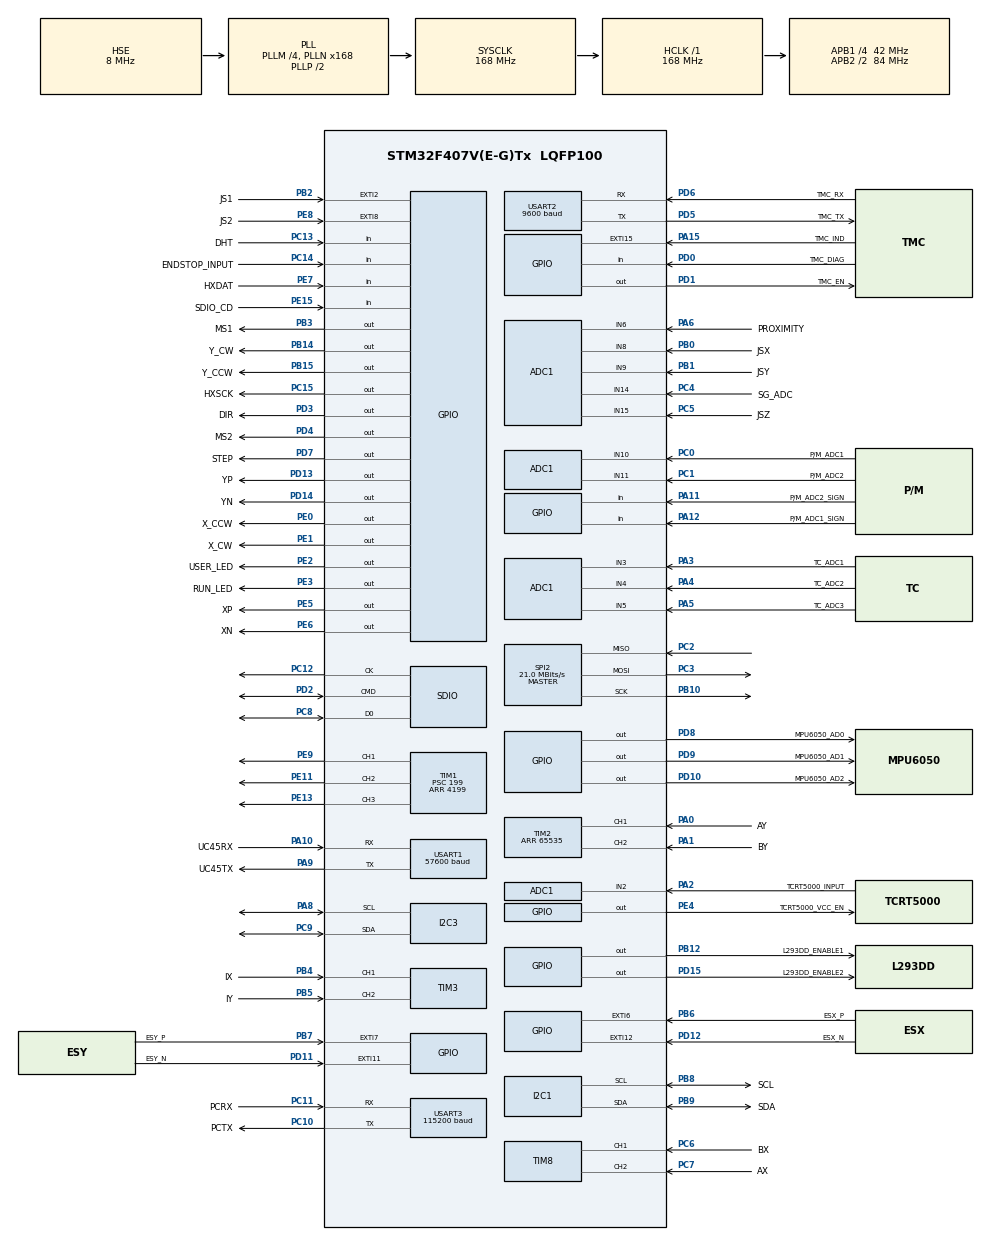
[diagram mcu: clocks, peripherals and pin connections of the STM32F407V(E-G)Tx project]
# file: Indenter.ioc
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ADC1.Channel-10\#ChannelRegularConversion=ADC_CHANNEL_6
ADC1.Channel-11\#ChannelRegularConversion=ADC_CHANNEL_8
ADC1.Channel-12\#ChannelRegularConversion=ADC_CHANNEL_9
ADC1.Channel-13\#ChannelRegularConversion=ADC_CHANNEL_10
ADC1.Channel-14\#ChannelRegularConversion=ADC_CHANNEL_11
ADC1.Channel-15\#ChannelRegularConversion=ADC_CHANNEL_14
ADC1.Channel-16\#ChannelRegularConversion=ADC_CHANNEL_15
ADC1.Channel-17\#ChannelRegularConversion=ADC_CHANNEL_TEMPSENSOR
ADC1.Channel-18\#ChannelRegularConversion=ADC_CHANNEL_VREFINT
ADC1.Channel-6\#ChannelRegularConversion=ADC_CHANNEL_2
ADC1.Channel-7\#ChannelRegularConversion=ADC_CHANNEL_3
ADC1.Channel-8\#ChannelRegularConversion=ADC_CHANNEL_4
ADC1.Channel-9\#ChannelRegularConversion=ADC_CHANNEL_5
ADC1.ContinuousConvMode=ENABLE
ADC1.DMAContinuousRequests=ENABLE
ADC1.EOCSelection=ADC_EOC_SEQ_CONV
ADC1.NbrOfConversion=13
ADC1.NbrOfConversionFlag=1
ADC1.Rank-10\#ChannelRegularConversion=5
ADC1.Rank-11\#ChannelRegularConversion=6
ADC1.Rank-12\#ChannelRegularConversion=7
ADC1.Rank-13\#ChannelRegularConversion=8
ADC1.Rank-14\#ChannelRegularConversion=9
ADC1.Rank-15\#ChannelRegularConversion=10
ADC1.Rank-16\#ChannelRegularConversion=11
ADC1.Rank-17\#ChannelRegularConversion=12
ADC1.Rank-18\#ChannelRegularConversion=13
ADC1.Rank-6\#ChannelRegularConversion=1
ADC1.Rank-7\#ChannelRegularConversion=2
ADC1.Rank-8\#ChannelRegularConversion=3
ADC1.Rank-9\#ChannelRegularConversion=4
ADC1.SamplingTime-10\#ChannelRegularConversion=ADC_SAMPLETIME_28CYCLES
ADC1.SamplingTime-11\#ChannelRegularConversion=ADC_SAMPLETIME_28CYCLES
ADC1.SamplingTime-12\#ChannelRegularConversion=ADC_SAMPLETIME_28CYCLES
ADC1.SamplingTime-13\#ChannelRegularConversion=ADC_SAMPLETIME_28CYCLES
ADC1.SamplingTime-14\#ChannelRegularConversion=ADC_SAMPLETIME_28CYCLES
ADC1.SamplingTime-15\#ChannelRegularConversion=ADC_SAMPLETIME_28CYCLES
ADC1.SamplingTime-16\#ChannelRegularConversion=ADC_SAMPLETIME_28CYCLES
ADC1.SamplingTime-17\#ChannelRegularConversion=ADC_SAMPLETIME_28CYCLES
ADC1.SamplingTime-18\#ChannelRegularConversion=ADC_SAMPLETIME_28CYCLES
ADC1.SamplingTime-6\#ChannelRegularConversion=ADC_SAMPLETIME_28CYCLES
ADC1.SamplingTime-7\#ChannelRegularConversion=ADC_SAMPLETIME_28CYCLES
ADC1.SamplingTime-8\#ChannelRegularConversion=ADC_SAMPLETIME_28CYCLES
ADC1.SamplingTime-9\#ChannelRegularConversion=ADC_SAMPLETIME_28CYCLES
ADC1.master=1
Dma.ADC1.0.Direction=DMA_PERIPH_TO_MEMORY
Dma.ADC1.0.FIFOMode=DMA_FIFOMODE_DISABLE
Dma.ADC1.0.Instance=DMA2_Stream0
Dma.ADC1.0.MemDataAlignment=DMA_MDATAALIGN_HALFWORD
Dma.ADC1.0.MemInc=DMA_MINC_ENABLE
Dma.ADC1.0.Mode=DMA_CIRCULAR
Dma.ADC1.0.PeriphDataAlignment=DMA_PDATAALIGN_HALFWORD
Dma.ADC1.0.PeriphInc=DMA_PINC_DISABLE
Dma.ADC1.0.Priority=DMA_PRIORITY_LOW
Dma.Request0=ADC1
FATFS.BSP.number=1
FATFS0.BSP.STBoard=false
FATFS0.BSP.api=Unknown
FATFS0.BSP.i2caddr=0
FATFS0.BSP.instance=PE15
FATFS0.BSP.ip=GPIO
FATFS0.BSP.mode=Input
FATFS0.BSP.name=Detect_SDIO
FATFS0.BSP.solution=PE15
Mcu.Family=STM32F4
Mcu.Name=STM32F407V(E-G)Tx
Mcu.Package=LQFP100
NVIC.DMA2_Stream0_IRQn=true\:2\:0\:true\:false\:true\:false\:true
NVIC.EXTI15_10_IRQn=true\:2\:0\:true\:false\:true\:true\:true
NVIC.EXTI2_IRQn=true\:2\:0\:true\:false\:true\:true\:true
NVIC.EXTI9_5_IRQn=true\:2\:0\:true\:false\:true\:true\:true
NVIC.PriorityGroup=NVIC_PRIORITYGROUP_4
NVIC.TIM1_BRK_TIM9_IRQn=true\:2\:0\:true\:false\:true\:true\:true
NVIC.TIM1_TRG_COM_TIM11_IRQn=true\:2\:0\:true\:false\:true\:true\:true
NVIC.TIM1_UP_TIM10_IRQn=true\:2\:0\:true\:false\:true\:true\:true
NVIC.TIM8_BRK_TIM12_IRQn=true\:2\:0\:true\:false\:true\:true\:true
NVIC.TIM8_UP_TIM13_IRQn=true\:2\:0\:true\:false\:true\:true\:true
NVIC.USART1_IRQn=true\:1\:0\:true\:false\:true\:true\:true
NVIC.USART2_IRQn=true\:1\:0\:true\:false\:true\:true\:true
NVIC.USART3_IRQn=true\:1\:0\:true\:false\:true\:true\:true
PA0-WKUP.GPIO_Label=AY
PA0-WKUP.Signal=S_TIM2_CH1_ETR
PA1.GPIO_Label=BY
PA1.Signal=S_TIM2_CH2
PA10.GPIO_Label=UC45RX
PA10.Mode=Asynchronous
PA10.Signal=USART1_RX
PA11.GPIO_Label=P/M_ADC2_SIGN
PA11.Signal=GPIO_Input
PA12.GPIO_Label=P/M_ADC1_SIGN
PA12.Signal=GPIO_Input
PA13.Mode=Serial_Wire
PA13.Signal=SYS_JTMS-SWDIO
PA14.Mode=Serial_Wire
PA14.Signal=SYS_JTCK-SWCLK
PA15.GPIO_Label=TMC_IND
PA15.Signal=GPXTI15
PA2.GPIO_Label=TCRT5000_INPUT
PA2.Signal=ADCx_IN2
PA3.GPIO_Label=TC_ADC1
PA3.Signal=ADCx_IN3
PA4.GPIO_Label=TC_ADC2
PA4.Signal=ADCx_IN4
PA5.GPIO_Label=TC_ADC3
PA5.Signal=ADCx_IN5
PA6.GPIO_Label=PROXIMITY
PA6.Signal=ADCx_IN6
PA8.Mode=I2C
PA8.Signal=I2C3_SCL
PA9.GPIO_Label=UC45TX
PA9.Mode=Asynchronous
PA9.Signal=USART1_TX
PB0.GPIO_Label=JSX
PB0.Signal=ADCx_IN8
PB1.GPIO_Label=JSY
PB1.Signal=ADCx_IN9
PB10.Mode=Full_Duplex_Master
PB10.Signal=SPI2_SCK
PB12.GPIO_Label=L293DD_ENABLE1
PB12.Signal=GPIO_Output
PB14.GPIO_Label=Y_CW
PB14.Signal=GPIO_Output
PB15.GPIO_Label=Y_CCW
PB15.Signal=GPIO_Output
PB2.GPIO_Label=JS1
PB2.GPIO_ModeDefaultEXTI=GPIO_MODE_IT_FALLING
PB2.GPIO_PuPd=GPIO_PULLUP
PB2.Signal=GPXTI2
PB3.GPIO_Label=MS1
PB3.Signal=GPIO_Output
PB4.GPIO_Label=IX
PB4.Signal=S_TIM3_CH1
PB5.GPIO_Label=IY
PB5.Signal=S_TIM3_CH2
PB6.GPIO_Label=ESX_P
PB6.GPIO_ModeDefaultEXTI=GPIO_MODE_IT_RISING_FALLING
PB6.Signal=GPXTI6
PB7.GPIO_Label=ESY_P
PB7.GPIO_ModeDefaultEXTI=GPIO_MODE_IT_RISING_FALLING
PB7.Signal=GPXTI7
PB8.GPIO_Label=SCL
PB8.Mode=I2C
PB8.Signal=I2C1_SCL
PB9.GPIO_Label=SDA
PB9.Mode=I2C
PB9.Signal=I2C1_SDA
PC0.GPIO_Label=P/M_ADC1
PC0.Signal=ADCx_IN10
PC1.GPIO_Label=P/M_ADC2
PC1.Signal=ADCx_IN11
PC10.GPIO_Label=PCTX
PC10.Mode=Asynchronous
PC10.Signal=USART3_TX
PC11.GPIO_Label=PCRX
PC11.Mode=Asynchronous
PC11.Signal=USART3_RX
PC12.Mode=SD_1_bit
PC12.Signal=SDIO_CK
PC13-ANTI_TAMP.GPIO_Label=DHT
PC13-ANTI_TAMP.Signal=GPIO_Input
PC14-OSC32_IN.GPIO_Label=ENDSTOP_INPUT
PC14-OSC32_IN.Signal=GPIO_Input
PC15-OSC32_OUT.GPIO_Label=HXSCK
PC15-OSC32_OUT.Signal=GPIO_Output
PC2.Mode=Full_Duplex_Master
PC2.Signal=SPI2_MISO
PC3.Mode=Full_Duplex_Master
PC3.Signal=SPI2_MOSI
PC4.GPIO_Label=SG_ADC
PC4.Signal=ADCx_IN14
PC5.GPIO_Label=JSZ
PC5.Signal=ADCx_IN15
PC6.GPIO_Label=BX
PC6.Signal=S_TIM8_CH1
PC7.GPIO_Label=AX
PC7.Signal=S_TIM8_CH2
PC8.Mode=SD_1_bit
PC8.Signal=SDIO_D0
PC9.Mode=I2C
PC9.Signal=I2C3_SDA
PD0.GPIO_Label=TMC_DIAG
PD0.Signal=GPIO_Input
PD1.GPIO_Label=TMC_EN
PD1.Signal=GPIO_Output
PD10.GPIO_Label=MPU6050_AD2
PD10.Signal=GPIO_Output
PD11.GPIO_Label=ESY_N
PD11.GPIO_ModeDefaultEXTI=GPIO_MODE_IT_RISING_FALLING
PD11.Signal=GPXTI11
PD12.GPIO_Label=ESX_N
PD12.GPIO_ModeDefaultEXTI=GPIO_MODE_IT_RISING_FALLING
PD12.Signal=GPXTI12
PD13.GPIO_Label=YP
PD13.Signal=GPIO_Output
PD14.GPIO_Label=YN
PD14.Signal=GPIO_Output
PD15.GPIO_Label=L293DD_ENABLE2
PD15.Signal=GPIO_Output
PD2.Mode=SD_1_bit
PD2.Signal=SDIO_CMD
PD3.GPIO_Label=DIR
PD3.Signal=GPIO_Output
PD4.GPIO_Label=MS2
PD4.Signal=GPIO_Output
PD5.GPIO_Label=TMC_TX
PD5.Mode=Asynchronous
PD5.Signal=USART2_TX
PD6.GPIO_Label=TMC_RX
PD6.Mode=Asynchronous
PD6.Signal=USART2_RX
PD7.GPIO_Label=STEP
PD7.Signal=GPIO_Output
PD8.GPIO_Label=MPU6050_AD0
PD8.Signal=GPIO_Output
PD9.GPIO_Label=MPU6050_AD1
PD9.Signal=GPIO_Output
PE0.GPIO_Label=X_CCW
PE0.Signal=GPIO_Output
PE1.GPIO_Label=X_CW
PE1.Signal=GPIO_Output
PE11.GPIO_ModeDefaultPP=GPIO_MODE_AF_PP
PE11.GPIO_PuPd=GPIO_NOPULL
PE11.GPIO_Speed=GPIO_SPEED_FREQ_LOW
PE11.Signal=S_TIM1_CH2
PE13.GPIO_ModeDefaultPP=GPIO_MODE_AF_PP
PE13.GPIO_PuPd=GPIO_NOPULL
PE13.GPIO_Speed=GPIO_SPEED_FREQ_LOW
PE13.Signal=S_TIM1_CH3
PE15.GPIO_Label=SDIO_CD
PE15.Signal=GPIO_Input
PE2.GPIO_Label=USER_LED
PE2.Signal=GPIO_Output
PE3.GPIO_Label=RUN_LED
PE3.Signal=GPIO_Output
PE4.GPIO_Label=TCRT5000_VCC_EN
PE4.Signal=GPIO_Output
PE5.GPIO_Label=XP
PE5.Signal=GPIO_Output
PE6.GPIO_Label=XN
PE6.Signal=GPIO_Output
PE7.GPIO_Label=HXDAT
PE7.Signal=GPIO_Input
PE8.GPIO_Label=JS2
PE8.GPIO_ModeDefaultEXTI=GPIO_MODE_IT_FALLING
PE8.GPIO_PuPd=GPIO_PULLUP
PE8.Signal=GPXTI8
PE9.GPIO_ModeDefaultPP=GPIO_MODE_AF_PP
PE9.GPIO_PuPd=GPIO_NOPULL
PE9.GPIO_Speed=GPIO_SPEED_FREQ_LOW
PE9.Signal=S_TIM1_CH1
PH0-OSC_IN.Mode=HSE-External-Oscillator
PH0-OSC_IN.Signal=RCC_OSC_IN
PH1-OSC_OUT.Mode=HSE-External-Oscillator
PH1-OSC_OUT.Signal=RCC_OSC_OUT
ProjectManager.HeapSize=0x200
ProjectManager.StackSize=0x400
ProjectManager.TargetToolchain=STM32CubeIDE
RCC.48MHZClocksFreq_Value=48000000
RCC.AHBFreq_Value=168000000
RCC.APB1CLKDivider=RCC_HCLK_DIV4
RCC.APB1Freq_Value=42000000
RCC.APB1TimFreq_Value=84000000
RCC.APB2CLKDivider=RCC_HCLK_DIV2
RCC.APB2Freq_Value=84000000
RCC.APB2TimFreq_Value=168000000
RCC.CortexFreq_Value=168000000
RCC.HCLKFreq_Value=168000000
RCC.HSE_VALUE=8000000
RCC.HSI_VALUE=16000000
RCC.LSE_VALUE=32768
RCC.PLLM=4
RCC.PLLN=168
RCC.PLLQ=7
RCC.PLLSourceVirtual=RCC_PLLSOURCE_HSE
RCC.SYSCLKFreq_VALUE=168000000
RCC.SYSCLKSource=RCC_SYSCLKSOURCE_PLLCLK
RCC.VCOOutputFreq_Value=336000000
SH.ADCx_IN10.0=ADC1_IN10,IN10
SH.ADCx_IN11.0=ADC1_IN11,IN11
SH.ADCx_IN14.0=ADC1_IN14,IN14
SH.ADCx_IN15.0=ADC1_IN15,IN15
SH.ADCx_IN2.0=ADC1_IN2,IN2
SH.ADCx_IN3.0=ADC1_IN3,IN3
SH.ADCx_IN4.0=ADC1_IN4,IN4
SH.ADCx_IN5.0=ADC1_IN5,IN5
SH.ADCx_IN6.0=ADC1_IN6,IN6
SH.ADCx_IN8.0=ADC1_IN8,IN8
SH.ADCx_IN9.0=ADC1_IN9,IN9
SH.S_TIM1_CH1.0=TIM1_CH1,PWM Generation1 CH1
SH.S_TIM1_CH2.0=TIM1_CH2,PWM Generation2 CH2
SH.S_TIM1_CH3.0=TIM1_CH3,PWM Generation3 CH3
SH.S_TIM2_CH1_ETR.0=TIM2_CH1,Encoder_Interface
SH.S_TIM2_CH2.0=TIM2_CH2,Encoder_Interface
SH.S_TIM3_CH1.0=TIM3_CH1,Encoder_Interface
SH.S_TIM3_CH2.0=TIM3_CH2,Encoder_Interface
SH.S_TIM8_CH1.0=TIM8_CH1,Encoder_Interface
SH.S_TIM8_CH2.0=TIM8_CH2,Encoder_Interface
SPI2.BaudRatePrescaler=SPI_BAUDRATEPRESCALER_2
SPI2.CalculateBaudRate=21.0 MBits/s
SPI2.Direction=SPI_DIRECTION_2LINES
SPI2.Mode=SPI_MODE_MASTER
SPI2.VirtualType=VM_MASTER
TIM1.Channel-PWM\ Generation1\ CH1=TIM_CHANNEL_1
TIM1.Channel-PWM\ Generation2\ CH2=TIM_CHANNEL_2
TIM1.Channel-PWM\ Generation3\ CH3=TIM_CHANNEL_3
TIM1.Period=4199
TIM1.Prescaler=199
TIM2.AutoReloadPreload=TIM_AUTORELOAD_PRELOAD_ENABLE
TIM2.EncoderMode=TIM_ENCODERMODE_TI12
TIM2.IC1Filter=0
TIM2.IC2Filter=0
TIM2.Period=65535
TIM3.AutoReloadPreload=TIM_AUTORELOAD_PRELOAD_ENABLE
TIM3.EncoderMode=TIM_ENCODERMODE_TI12
TIM3.IC1Filter=0
TIM3.IC2Filter=0
TIM8.AutoReloadPreload=TIM_AUTORELOAD_PRELOAD_ENABLE
TIM8.EncoderMode=TIM_ENCODERMODE_TI12
TIM8.IC1Filter=0
TIM8.IC2Filter=0
USART1.BaudRate=57600
USART1.VirtualMode=VM_ASYNC
USART2.BaudRate=9600
USART2.VirtualMode=VM_ASYNC
USART3.BaudRate=115200
USART3.VirtualMode=VM_ASYNC
VP_ADC1_TempSens_Input.Mode=IN-TempSens
VP_ADC1_Vref_Input.Mode=IN-Vrefint
VP_FATFS_VS_SDIO.Mode=SDIO
VP_TIM10_VS_ClockSourceINT.Mode=Enable_Timer
VP_TIM11_VS_ClockSourceINT.Mode=Enable_Timer
VP_TIM12_VS_ClockSourceINT.Mode=Internal
VP_TIM13_VS_ClockSourceINT.Mode=Enable_Timer
VP_TIM9_VS_ClockSourceINT.Mode=Internal
board=custom

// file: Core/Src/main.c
/* USER CODE BEGIN Header */
/**
 * INDENTER CONTROL CARD V1 PROGRAM
  ******************************************************************************
  * @file           : main.c
  * @brief          : Main program body
  ******************************************************************************
  * @attention
  *
  * <h2><center>&copy; Copyright (c) 2021 STMicroelectronics.
  * All rights reserved.</center></h2>
  *
  * This software component is licensed by ST under BSD 3-Clause license,
  * the "License"; You may not use this file except in compliance with the
  * License. You may obtain a copy of the License at:
  *                        opensource.org/licenses/BSD-3-Clause
  *
  ******************************************************************************
  */
/* USER CODE END Header */
#include "main.h"
#include "fatfs.h"

/* USER CODE BEGIN Includes */
#include "stdio.h"
#include "struct.h"
#include "string.h"
#include "stdint.h"
#include "stdlib.h"
#include "math.h"
#include "timer.h"
#include "uart.h"
#include "adc.h"
#include "HX711.h"
#include "DHT.h"
#include "accel.h"
#include "experiment.h"
#include "ext_it.h"
#include "heater.h"
#include "encoder.h"
#include "pc_uart.h"
/* USER CODE END Includes */

/* USER CODE BEGIN PD */
#define DEBUG 1

#define UC45_RESP				1

#define DATA_FLASH_START_ADDR 0x800F000

/* USER CODE END PD */

/* USER CODE BEGIN PM */
#if DEBUG == 1
#define consoleWrite(args ...) printf(args)
#else
#define consoleWrite(args ...)
#endif

/* USER CODE END PM */

ADC_HandleTypeDef hadc1;
DMA_HandleTypeDef hdma_adc1;

I2C_HandleTypeDef hi2c1;
I2C_HandleTypeDef hi2c3;

SD_HandleTypeDef hsd;

SPI_HandleTypeDef hspi2;

TIM_HandleTypeDef htim1;
TIM_HandleTypeDef htim2;
TIM_HandleTypeDef htim3;
TIM_HandleTypeDef htim8;
TIM_HandleTypeDef htim9;
TIM_HandleTypeDef htim10;
TIM_HandleTypeDef htim11;
TIM_HandleTypeDef htim12;
TIM_HandleTypeDef htim13;

UART_HandleTypeDef huart1;
UART_HandleTypeDef huart2;
UART_HandleTypeDef huart3;

/* USER CODE BEGIN PV */

INITIALCOM INIT0;
EXPERIMENT expin[100];
EXPERIMENTrx exprx[100];
CALIBRATION calib;
CALIBRATIONrx calibrx;

//DHT
DHT_DataTypedef instanthum;

//HX711
HX711 instant;
int tmpVal;
//Accelerometer
uint16_t mpu[3] = {0};
//adc
char datasender[30];
uint32_t adcBuff[1300] = {0};
uint16_t adcData[13] = {0};
int extcon=0;
int joyen=0;
int joyint1=0;
int joyint2=0;
int delaymic=0;
int loadcon=0;
int contact=0;
int contsend=0;

extern int speedmode;
extern int pccom;
extern UARTCOM * _uartcom3;
extern UARTCOM pcInit;
extern int sendexp;//timer2 control execute exp
extern int stopmot;
extern int osc;//timer2 control oscillation activate
extern int retracting;
extern int automot;
extern int dir;
extern int sensdist;
extern int eqstep;
extern enum approach app;
extern uint8_t isAutoApproach;
extern int stepsay;
uint8_t dcMotor = 1;
uint16_t adcVal[13];
uint8_t kilo;
extern uint32_t x_enc[2];
extern uint32_t y_enc[2];
extern uint32_t i_enc[2];
extern int movxy;
extern int heatDuty[3];

int isHXcom=0;

/* USER CODE END PV */

void SystemClock_Config(void);
static void MX_GPIO_Init(void);
static void MX_DMA_Init(void);
static void MX_TIM8_Init(void);
static void MX_I2C3_Init(void);
static void MX_USART1_UART_Init(void);
static void MX_I2C1_Init(void);
static void MX_SPI2_Init(void);
static void MX_SDIO_SD_Init(void);
static void MX_USART2_UART_Init(void);
static void MX_USART3_UART_Init(void);
static void MX_TIM2_Init(void);
static void MX_TIM3_Init(void);
static void MX_ADC1_Init(void);
static void MX_TIM1_Init(void);
static void MX_TIM9_Init(void);
static void MX_TIM10_Init(void);
static void MX_TIM11_Init(void);
static void MX_TIM12_Init(void);
static void MX_TIM13_Init(void);

/* USER CODE BEGIN 0 */
int _write(int file, char *ptr, int len)
{
	int DataIdx;

	for (DataIdx = 0; DataIdx < len; DataIdx++)
	{
		ITM_SendChar(*ptr++);
	}
	return len;
}

/* USER CODE END 0 */

int main(void)
{
  /* USER CODE BEGIN 1 */
	char strArr[10];
  /* USER CODE END 1 */

  /* MCU Configuration--------------------------------------------------------*/

  /* Reset of all peripherals, Initializes the Flash interface and the Systick. */
  HAL_Init();

  /* USER CODE BEGIN Init */
  UartInit();
  /* USER CODE END Init */

  /* Initialize all configured peripherals */
  MX_GPIO_Init();
  MX_DMA_Init();
  MX_TIM8_Init();
  MX_I2C3_Init();
  MX_USART1_UART_Init();
  MX_I2C1_Init();
  MX_SPI2_Init();
  MX_SDIO_SD_Init();
  MX_USART2_UART_Init();
  MX_USART3_UART_Init();
  MX_TIM2_Init();
  MX_TIM3_Init();
  MX_ADC1_Init();
  MX_TIM1_Init();
  MX_TIM9_Init();
  MX_TIM10_Init();
  MX_TIM11_Init();
  MX_TIM12_Init();
  MX_FATFS_Init();
  MX_TIM13_Init();
  /* USER CODE BEGIN 2 */
  instant.gpioData = HXDAT_GPIO_Port;
  instant.gpioSck = HXSCK_GPIO_Port;
  instant.pinData = HXDAT_Pin;
  instant.pinSck = HXSCK_Pin;
  instant.gain = 3;
  HX711_Init(instant);
  instant = HX711_Tare(instant, 15);
  uint32_t flashsize =*(uint32_t *) FLASHSIZE_BASE;
  UNUSED(flashsize);
  HAL_ADC_Start_DMA(&hadc1, adcBuff, 1300);
  HAL_GPIO_WritePin(TMC_EN_GPIO_Port, TMC_EN_Pin,GPIO_PIN_SET);
  TimeSet(&htim11, 100000);
  HAL_TIM_Encoder_Start(&htim2, TIM_CHANNEL_ALL);
  HAL_TIM_Encoder_Start(&htim8, TIM_CHANNEL_ALL);
  __HAL_TIM_SET_COMPARE(&htim1,TIM_CHANNEL_1,0);
  __HAL_TIM_SET_COMPARE(&htim1,TIM_CHANNEL_2,0);
  __HAL_TIM_SET_COMPARE(&htim1,TIM_CHANNEL_3,0);
  HAL_TIM_PWM_Start(&htim1, TIM_CHANNEL_1);
  HAL_TIM_PWM_Start(&htim1, TIM_CHANNEL_2);
  HAL_TIM_PWM_Start(&htim1, TIM_CHANNEL_3);
  TimeSet(&htim13, 100000);
  TimeSet(&htim12, 10000);
  /* USER CODE END 2 */

  /* Infinite loop */
  /* USER CODE BEGIN WHILE */
  while (1)
  {
	  if(isAutoApproach==1){
		  isAutoApproach=6;
		  autoApproach(-1);
	  }
    /* USER CODE END WHILE */

  }
}

void SystemClock_Config(void)
{
  RCC_OscInitTypeDef RCC_OscInitStruct = {0};
  RCC_ClkInitTypeDef RCC_ClkInitStruct = {0};

  /** Configure the main internal regulator output voltage
  */
  __HAL_RCC_PWR_CLK_ENABLE();
  __HAL_PWR_VOLTAGESCALING_CONFIG(PWR_REGULATOR_VOLTAGE_SCALE1);
  /** Initializes the RCC Oscillators according to the specified parameters
  * in the RCC_OscInitTypeDef structure.
  */
  RCC_OscInitStruct.OscillatorType = RCC_OSCILLATORTYPE_HSE;
  RCC_OscInitStruct.HSEState = RCC_HSE_ON;
  RCC_OscInitStruct.PLL.PLLState = RCC_PLL_ON;
  RCC_OscInitStruct.PLL.PLLSource = RCC_PLLSOURCE_HSE;
  RCC_OscInitStruct.PLL.PLLM = 4;
  RCC_OscInitStruct.PLL.PLLN = 168;
  RCC_OscInitStruct.PLL.PLLP = RCC_PLLP_DIV2;
  RCC_OscInitStruct.PLL.PLLQ = 7;
  if (HAL_RCC_OscConfig(&RCC_OscInitStruct) != HAL_OK)
  {
    Error_Handler();
  }
  /** Initializes the CPU, AHB and APB buses clocks
  */
  RCC_ClkInitStruct.ClockType = RCC_CLOCKTYPE_HCLK|RCC_CLOCKTYPE_SYSCLK
                              |RCC_CLOCKTYPE_PCLK1|RCC_CLOCKTYPE_PCLK2;
  RCC_ClkInitStruct.SYSCLKSource = RCC_SYSCLKSOURCE_PLLCLK;
  RCC_ClkInitStruct.AHBCLKDivider = RCC_SYSCLK_DIV1;
  RCC_ClkInitStruct.APB1CLKDivider = RCC_HCLK_DIV4;
  RCC_ClkInitStruct.APB2CLKDivider = RCC_HCLK_DIV2;

  if (HAL_RCC_ClockConfig(&RCC_ClkInitStruct, FLASH_LATENCY_5) != HAL_OK)
  {
    Error_Handler();
  }
}

static void MX_ADC1_Init(void)
{

  ADC_ChannelConfTypeDef sConfig = {0};

  /** Configure the global features of the ADC (Clock, Resolution, Data Alignment and number of conversion)
  */
  hadc1.Instance = ADC1;
  hadc1.Init.ClockPrescaler = ADC_CLOCK_SYNC_PCLK_DIV4;
  hadc1.Init.Resolution = ADC_RESOLUTION_12B;
  hadc1.Init.ScanConvMode = ENABLE;
  hadc1.Init.ContinuousConvMode = ENABLE;
  hadc1.Init.DiscontinuousConvMode = DISABLE;
  hadc1.Init.ExternalTrigConvEdge = ADC_EXTERNALTRIGCONVEDGE_NONE;
  hadc1.Init.ExternalTrigConv = ADC_SOFTWARE_START;
  hadc1.Init.DataAlign = ADC_DATAALIGN_RIGHT;
  hadc1.Init.NbrOfConversion = 13;
  hadc1.Init.DMAContinuousRequests = ENABLE;
  hadc1.Init.EOCSelection = ADC_EOC_SEQ_CONV;
  if (HAL_ADC_Init(&hadc1) != HAL_OK)
  {
    Error_Handler();
  }
  /** Configure for the selected ADC regular channel its corresponding rank in the sequencer and its sample time.
  */
  sConfig.Channel = ADC_CHANNEL_2;
  sConfig.Rank = 1;
  sConfig.SamplingTime = ADC_SAMPLETIME_28CYCLES;
  if (HAL_ADC_ConfigChannel(&hadc1, &sConfig) != HAL_OK)
  {
    Error_Handler();
  }
  /** Configure for the selected ADC regular channel its corresponding rank in the sequencer and its sample time.
  */
  sConfig.Channel = ADC_CHANNEL_3;
  sConfig.Rank = 2;
  if (HAL_ADC_ConfigChannel(&hadc1, &sConfig) != HAL_OK)
  {
    Error_Handler();
  }
  /** Configure for the selected ADC regular channel its corresponding rank in the sequencer and its sample time.
  */
  sConfig.Channel = ADC_CHANNEL_4;
  sConfig.Rank = 3;
  if (HAL_ADC_ConfigChannel(&hadc1, &sConfig) != HAL_OK)
  {
    Error_Handler();
  }
  /** Configure for the selected ADC regular channel its corresponding rank in the sequencer and its sample time.
  */
  sConfig.Channel = ADC_CHANNEL_5;
  sConfig.Rank = 4;
  if (HAL_ADC_ConfigChannel(&hadc1, &sConfig) != HAL_OK)
  {
    Error_Handler();
  }
  /** Configure for the selected ADC regular channel its corresponding rank in the sequencer and its sample time.
  */
  sConfig.Channel = ADC_CHANNEL_6;
  sConfig.Rank = 5;
  if (HAL_ADC_ConfigChannel(&hadc1, &sConfig) != HAL_OK)
  {
    Error_Handler();
  }
  /** Configure for the selected ADC regular channel its corresponding rank in the sequencer and its sample time.
  */
  sConfig.Channel = ADC_CHANNEL_8;
  sConfig.Rank = 6;
  if (HAL_ADC_ConfigChannel(&hadc1, &sConfig) != HAL_OK)
  {
    Error_Handler();
  }
  /** Configure for the selected ADC regular channel its corresponding rank in the sequencer and its sample time.
  */
  sConfig.Channel = ADC_CHANNEL_9;
  sConfig.Rank = 7;
  if (HAL_ADC_ConfigChannel(&hadc1, &sConfig) != HAL_OK)
  {
    Error_Handler();
  }
  /** Configure for the selected ADC regular channel its corresponding rank in the sequencer and its sample time.
  */
  sConfig.Channel = ADC_CHANNEL_10;
  sConfig.Rank = 8;
  if (HAL_ADC_ConfigChannel(&hadc1, &sConfig) != HAL_OK)
  {
    Error_Handler();
  }
  /** Configure for the selected ADC regular channel its corresponding rank in the sequencer and its sample time.
  */
  sConfig.Channel = ADC_CHANNEL_11;
  sConfig.Rank = 9;
  if (HAL_ADC_ConfigChannel(&hadc1, &sConfig) != HAL_OK)
  {
    Error_Handler();
  }
  /** Configure for the selected ADC regular channel its corresponding rank in the sequencer and its sample time.
  */
  sConfig.Channel = ADC_CHANNEL_14;
  sConfig.Rank = 10;
  if (HAL_ADC_ConfigChannel(&hadc1, &sConfig) != HAL_OK)
  {
    Error_Handler();
  }
  /** Configure for the selected ADC regular channel its corresponding rank in the sequencer and its sample time.
  */
  sConfig.Channel = ADC_CHANNEL_15;
  sConfig.Rank = 11;
  if (HAL_ADC_ConfigChannel(&hadc1, &sConfig) != HAL_OK)
  {
    Error_Handler();
  }
  /** Configure for the selected ADC regular channel its corresponding rank in the sequencer and its sample time.
  */
  sConfig.Channel = ADC_CHANNEL_TEMPSENSOR;
  sConfig.Rank = 12;
  if (HAL_ADC_ConfigChannel(&hadc1, &sConfig) != HAL_OK)
  {
    Error_Handler();
  }
  /** Configure for the selected ADC regular channel its corresponding rank in the sequencer and its sample time.
  */
  sConfig.Channel = ADC_CHANNEL_VREFINT;
  sConfig.Rank = 13;
  if (HAL_ADC_ConfigChannel(&hadc1, &sConfig) != HAL_OK)
  {
    Error_Handler();
  }

}

static void MX_I2C1_Init(void)
{

  hi2c1.Instance = I2C1;
  hi2c1.Init.ClockSpeed = 100000;
  hi2c1.Init.DutyCycle = I2C_DUTYCYCLE_2;
  hi2c1.Init.OwnAddress1 = 0;
  hi2c1.Init.AddressingMode = I2C_ADDRESSINGMODE_7BIT;
  hi2c1.Init.DualAddressMode = I2C_DUALADDRESS_DISABLE;
  hi2c1.Init.OwnAddress2 = 0;
  hi2c1.Init.GeneralCallMode = I2C_GENERALCALL_DISABLE;
  hi2c1.Init.NoStretchMode = I2C_NOSTRETCH_DISABLE;
  if (HAL_I2C_Init(&hi2c1) != HAL_OK)
  {
    Error_Handler();
  }

}

static void MX_I2C3_Init(void)
{

  hi2c3.Instance = I2C3;
  hi2c3.Init.ClockSpeed = 100000;
  hi2c3.Init.DutyCycle = I2C_DUTYCYCLE_2;
  hi2c3.Init.OwnAddress1 = 0;
  hi2c3.Init.AddressingMode = I2C_ADDRESSINGMODE_7BIT;
  hi2c3.Init.DualAddressMode = I2C_DUALADDRESS_DISABLE;
  hi2c3.Init.OwnAddress2 = 0;
  hi2c3.Init.GeneralCallMode = I2C_GENERALCALL_DISABLE;
  hi2c3.Init.NoStretchMode = I2C_NOSTRETCH_DISABLE;
  if (HAL_I2C_Init(&hi2c3) != HAL_OK)
  {
    Error_Handler();
  }

}

static void MX_SDIO_SD_Init(void)
{

  hsd.Instance = SDIO;
  hsd.Init.ClockEdge = SDIO_CLOCK_EDGE_RISING;
  hsd.Init.ClockBypass = SDIO_CLOCK_BYPASS_DISABLE;
  hsd.Init.ClockPowerSave = SDIO_CLOCK_POWER_SAVE_DISABLE;
  hsd.Init.BusWide = SDIO_BUS_WIDE_1B;
  hsd.Init.HardwareFlowControl = SDIO_HARDWARE_FLOW_CONTROL_DISABLE;
  hsd.Init.ClockDiv = 0;

}

static void MX_SPI2_Init(void)
{

  /* SPI2 parameter configuration*/
  hspi2.Instance = SPI2;
  hspi2.Init.Mode = SPI_MODE_MASTER;
  hspi2.Init.Direction = SPI_DIRECTION_2LINES;
  hspi2.Init.DataSize = SPI_DATASIZE_8BIT;
  hspi2.Init.CLKPolarity = SPI_POLARITY_LOW;
  hspi2.Init.CLKPhase = SPI_PHASE_1EDGE;
  hspi2.Init.NSS = SPI_NSS_SOFT;
  hspi2.Init.BaudRatePrescaler = SPI_BAUDRATEPRESCALER_2;
  hspi2.Init.FirstBit = SPI_FIRSTBIT_MSB;
  hspi2.Init.TIMode = SPI_TIMODE_DISABLE;
  hspi2.Init.CRCCalculation = SPI_CRCCALCULATION_DISABLE;
  hspi2.Init.CRCPolynomial = 10;
  if (HAL_SPI_Init(&hspi2) != HAL_OK)
  {
    Error_Handler();
  }

}

static void MX_TIM1_Init(void)
{

  TIM_MasterConfigTypeDef sMasterConfig = {0};
  TIM_OC_InitTypeDef sConfigOC = {0};
  TIM_BreakDeadTimeConfigTypeDef sBreakDeadTimeConfig = {0};

  htim1.Instance = TIM1;
  htim1.Init.Prescaler = 199;
  htim1.Init.CounterMode = TIM_COUNTERMODE_UP;
  htim1.Init.Period = 4199;
  htim1.Init.ClockDivision = TIM_CLOCKDIVISION_DIV1;
  htim1.Init.RepetitionCounter = 0;
  htim1.Init.AutoReloadPreload = TIM_AUTORELOAD_PRELOAD_DISABLE;
  if (HAL_TIM_PWM_Init(&htim1) != HAL_OK)
  {
    Error_Handler();
  }
  sMasterConfig.MasterOutputTrigger = TIM_TRGO_RESET;
  sMasterConfig.MasterSlaveMode = TIM_MASTERSLAVEMODE_DISABLE;
  if (HAL_TIMEx_MasterConfigSynchronization(&htim1, &sMasterConfig) != HAL_OK)
  {
    Error_Handler();
  }
  sConfigOC.OCMode = TIM_OCMODE_PWM1;
  sConfigOC.Pulse = 0;
  sConfigOC.OCPolarity = TIM_OCPOLARITY_HIGH;
  sConfigOC.OCNPolarity = TIM_OCNPOLARITY_HIGH;
  sConfigOC.OCFastMode = TIM_OCFAST_DISABLE;
  sConfigOC.OCIdleState = TIM_OCIDLESTATE_RESET;
  sConfigOC.OCNIdleState = TIM_OCNIDLESTATE_RESET;
  if (HAL_TIM_PWM_ConfigChannel(&htim1, &sConfigOC, TIM_CHANNEL_1) != HAL_OK)
  {
    Error_Handler();
  }
  if (HAL_TIM_PWM_ConfigChannel(&htim1, &sConfigOC, TIM_CHANNEL_2) != HAL_OK)
  {
    Error_Handler();
  }
  if (HAL_TIM_PWM_ConfigChannel(&htim1, &sConfigOC, TIM_CHANNEL_3) != HAL_OK)
  {
    Error_Handler();
  }
  sBreakDeadTimeConfig.OffStateRunMode = TIM_OSSR_DISABLE;
  sBreakDeadTimeConfig.OffStateIDLEMode = TIM_OSSI_DISABLE;
  sBreakDeadTimeConfig.LockLevel = TIM_LOCKLEVEL_OFF;
  sBreakDeadTimeConfig.DeadTime = 0;
  sBreakDeadTimeConfig.BreakState = TIM_BREAK_DISABLE;
  sBreakDeadTimeConfig.BreakPolarity = TIM_BREAKPOLARITY_HIGH;
  sBreakDeadTimeConfig.AutomaticOutput = TIM_AUTOMATICOUTPUT_DISABLE;
  if (HAL_TIMEx_ConfigBreakDeadTime(&htim1, &sBreakDeadTimeConfig) != HAL_OK)
  {
    Error_Handler();
  }
  HAL_TIM_MspPostInit(&htim1);

}

static void MX_TIM2_Init(void)
{

  TIM_Encoder_InitTypeDef sConfig = {0};
  TIM_MasterConfigTypeDef sMasterConfig = {0};

  htim2.Instance = TIM2;
  htim2.Init.Prescaler = 0;
  htim2.Init.CounterMode = TIM_COUNTERMODE_UP;
  htim2.Init.Period = 65535;
  htim2.Init.ClockDivision = TIM_CLOCKDIVISION_DIV1;
  htim2.Init.AutoReloadPreload = TIM_AUTORELOAD_PRELOAD_ENABLE;
  sConfig.EncoderMode = TIM_ENCODERMODE_TI12;
  sConfig.IC1Polarity = TIM_ICPOLARITY_RISING;
  sConfig.IC1Selection = TIM_ICSELECTION_DIRECTTI;
  sConfig.IC1Prescaler = TIM_ICPSC_DIV1;
  sConfig.IC1Filter = 0;
  sConfig.IC2Polarity = TIM_ICPOLARITY_RISING;
  sConfig.IC2Selection = TIM_ICSELECTION_DIRECTTI;
  sConfig.IC2Prescaler = TIM_ICPSC_DIV1;
  sConfig.IC2Filter = 0;
  if (HAL_TIM_Encoder_Init(&htim2, &sConfig) != HAL_OK)
  {
    Error_Handler();
  }
  sMasterConfig.MasterOutputTrigger = TIM_TRGO_RESET;
  sMasterConfig.MasterSlaveMode = TIM_MASTERSLAVEMODE_DISABLE;
  if (HAL_TIMEx_MasterConfigSynchronization(&htim2, &sMasterConfig) != HAL_OK)
  {
    Error_Handler();
  }

}

static void MX_TIM3_Init(void)
{

  TIM_Encoder_InitTypeDef sConfig = {0};
  TIM_MasterConfigTypeDef sMasterConfig = {0};

  htim3.Instance = TIM3;
  htim3.Init.Prescaler = 0;
  htim3.Init.CounterMode = TIM_COUNTERMODE_UP;
  htim3.Init.Period = 65535;
  htim3.Init.ClockDivision = TIM_CLOCKDIVISION_DIV1;
  htim3.Init.AutoReloadPreload = TIM_AUTORELOAD_PRELOAD_ENABLE;
  sConfig.EncoderMode = TIM_ENCODERMODE_TI12;
  sConfig.IC1Polarity = TIM_ICPOLARITY_RISING;
  sConfig.IC1Selection = TIM_ICSELECTION_DIRECTTI;
  sConfig.IC1Prescaler = TIM_ICPSC_DIV1;
  sConfig.IC1Filter = 0;
  sConfig.IC2Polarity = TIM_ICPOLARITY_RISING;
  sConfig.IC2Selection = TIM_ICSELECTION_DIRECTTI;
  sConfig.IC2Prescaler = TIM_ICPSC_DIV1;
  sConfig.IC2Filter = 0;
  if (HAL_TIM_Encoder_Init(&htim3, &sConfig) != HAL_OK)
  {
    Error_Handler();
  }
  sMasterConfig.MasterOutputTrigger = TIM_TRGO_RESET;
  sMasterConfig.MasterSlaveMode = TIM_MASTERSLAVEMODE_DISABLE;
  if (HAL_TIMEx_MasterConfigSynchronization(&htim3, &sMasterConfig) != HAL_OK)
  {
    Error_Handler();
  }

}

static void MX_TIM8_Init(void)
{

  TIM_Encoder_InitTypeDef sConfig = {0};
  TIM_MasterConfigTypeDef sMasterConfig = {0};

  htim8.Instance = TIM8;
  htim8.Init.Prescaler = 0;
  htim8.Init.CounterMode = TIM_COUNTERMODE_UP;
  htim8.Init.Period = 65535;
  htim8.Init.ClockDivision = TIM_CLOCKDIVISION_DIV1;
  htim8.Init.RepetitionCounter = 0;
  htim8.Init.AutoReloadPreload = TIM_AUTORELOAD_PRELOAD_ENABLE;
  sConfig.EncoderMode = TIM_ENCODERMODE_TI12;
  sConfig.IC1Polarity = TIM_ICPOLARITY_RISING;
  sConfig.IC1Selection = TIM_ICSELECTION_DIRECTTI;
  sConfig.IC1Prescaler = TIM_ICPSC_DIV1;
  sConfig.IC1Filter = 0;
  sConfig.IC2Polarity = TIM_ICPOLARITY_RISING;
  sConfig.IC2Selection = TIM_ICSELECTION_DIRECTTI;
  sConfig.IC2Prescaler = TIM_ICPSC_DIV1;
  sConfig.IC2Filter = 0;
  if (HAL_TIM_Encoder_Init(&htim8, &sConfig) != HAL_OK)
  {
    Error_Handler();
  }
  sMasterConfig.MasterOutputTrigger = TIM_TRGO_RESET;
  sMasterConfig.MasterSlaveMode = TIM_MASTERSLAVEMODE_DISABLE;
  if (HAL_TIMEx_MasterConfigSynchronization(&htim8, &sMasterConfig) != HAL_OK)
  {
    Error_Handler();
  }

}

static void MX_TIM9_Init(void)
{

  TIM_ClockConfigTypeDef sClockSourceConfig = {0};

  htim9.Instance = TIM9;
  htim9.Init.Prescaler = 0;
  htim9.Init.CounterMode = TIM_COUNTERMODE_UP;
  htim9.Init.Period = 65535;
  htim9.Init.ClockDivision = TIM_CLOCKDIVISION_DIV1;
  htim9.Init.AutoReloadPreload = TIM_AUTORELOAD_PRELOAD_DISABLE;
  if (HAL_TIM_Base_Init(&htim9) != HAL_OK)
  {
    Error_Handler();
  }
  sClockSourceConfig.ClockSource = TIM_CLOCKSOURCE_INTERNAL;
  if (HAL_TIM_ConfigClockSource(&htim9, &sClockSourceConfig) != HAL_OK)
  {
    Error_Handler();
  }

}

static void MX_TIM10_Init(void)
{

  htim10.Instance = TIM10;
  htim10.Init.Prescaler = 0;
  htim10.Init.CounterMode = TIM_COUNTERMODE_UP;
  htim10.Init.Period = 65535;
  htim10.Init.ClockDivision = TIM_CLOCKDIVISION_DIV1;
  htim10.Init.AutoReloadPreload = TIM_AUTORELOAD_PRELOAD_DISABLE;
  if (HAL_TIM_Base_Init(&htim10) != HAL_OK)
  {
    Error_Handler();
  }

}

static void MX_TIM11_Init(void)
{

  htim11.Instance = TIM11;
  htim11.Init.Prescaler = 0;
  htim11.Init.CounterMode = TIM_COUNTERMODE_UP;
  htim11.Init.Period = 65535;
  htim11.Init.ClockDivision = TIM_CLOCKDIVISION_DIV1;
  htim11.Init.AutoReloadPreload = TIM_AUTORELOAD_PRELOAD_DISABLE;
  if (HAL_TIM_Base_Init(&htim11) != HAL_OK)
  {
    Error_Handler();
  }

}

static void MX_TIM12_Init(void)
{

  TIM_ClockConfigTypeDef sClockSourceConfig = {0};

  htim12.Instance = TIM12;
  htim12.Init.Prescaler = 0;
  htim12.Init.CounterMode = TIM_COUNTERMODE_UP;
  htim12.Init.Period = 65535;
  htim12.Init.ClockDivision = TIM_CLOCKDIVISION_DIV1;
  htim12.Init.AutoReloadPreload = TIM_AUTORELOAD_PRELOAD_DISABLE;
  if (HAL_TIM_Base_Init(&htim12) != HAL_OK)
  {
    Error_Handler();
  }
  sClockSourceConfig.ClockSource = TIM_CLOCKSOURCE_INTERNAL;
  if (HAL_TIM_ConfigClockSource(&htim12, &sClockSourceConfig) != HAL_OK)
  {
    Error_Handler();
  }

}

static void MX_TIM13_Init(void)
{

  htim13.Instance = TIM13;
  htim13.Init.Prescaler = 0;
  htim13.Init.CounterMode = TIM_COUNTERMODE_UP;
  htim13.Init.Period = 65535;
  htim13.Init.ClockDivision = TIM_CLOCKDIVISION_DIV1;
  htim13.Init.AutoReloadPreload = TIM_AUTORELOAD_PRELOAD_DISABLE;
  if (HAL_TIM_Base_Init(&htim13) != HAL_OK)
  {
    Error_Handler();
  }

}

static void MX_USART1_UART_Init(void)
{

  huart1.Instance = USART1;
  huart1.Init.BaudRate = 57600;
  huart1.Init.WordLength = UART_WORDLENGTH_8B;
  huart1.Init.StopBits = UART_STOPBITS_1;
  huart1.Init.Parity = UART_PARITY_NONE;
  huart1.Init.Mode = UART_MODE_TX_RX;
  huart1.Init.HwFlowCtl = UART_HWCONTROL_NONE;
  huart1.Init.OverSampling = UART_OVERSAMPLING_16;
  if (HAL_UART_Init(&huart1) != HAL_OK)
  {
    Error_Handler();
  }

}

static void MX_USART2_UART_Init(void)
{

  huart2.Instance = USART2;
  huart2.Init.BaudRate = 9600;
  huart2.Init.WordLength = UART_WORDLENGTH_8B;
  huart2.Init.StopBits = UART_STOPBITS_1;
  huart2.Init.Parity = UART_PARITY_NONE;
  huart2.Init.Mode = UART_MODE_TX_RX;
  huart2.Init.HwFlowCtl = UART_HWCONTROL_NONE;
  huart2.Init.OverSampling = UART_OVERSAMPLING_16;
  if (HAL_UART_Init(&huart2) != HAL_OK)
  {
    Error_Handler();
  }

}

static void MX_USART3_UART_Init(void)
{

  huart3.Instance = USART3;
  huart3.Init.BaudRate = 115200;
  huart3.Init.WordLength = UART_WORDLENGTH_8B;
  huart3.Init.StopBits = UART_STOPBITS_1;
  huart3.Init.Parity = UART_PARITY_NONE;
  huart3.Init.Mode = UART_MODE_TX_RX;
  huart3.Init.HwFlowCtl = UART_HWCONTROL_NONE;
  huart3.Init.OverSampling = UART_OVERSAMPLING_16;
  if (HAL_UART_Init(&huart3) != HAL_OK)
  {
    Error_Handler();
  }

}

static void MX_DMA_Init(void)
{

  /* DMA controller clock enable */
  __HAL_RCC_DMA2_CLK_ENABLE();

  /* DMA interrupt init */
  /* DMA2_Stream0_IRQn interrupt configuration */
  HAL_NVIC_SetPriority(DMA2_Stream0_IRQn, 2, 0);
  HAL_NVIC_EnableIRQ(DMA2_Stream0_IRQn);

}

static void MX_GPIO_Init(void)
{
  GPIO_InitTypeDef GPIO_InitStruct = {0};

  /* GPIO Ports Clock Enable */
  __HAL_RCC_GPIOE_CLK_ENABLE();
  __HAL_RCC_GPIOC_CLK_ENABLE();
  __HAL_RCC_GPIOH_CLK_ENABLE();
  __HAL_RCC_GPIOA_CLK_ENABLE();
  __HAL_RCC_GPIOB_CLK_ENABLE();
  __HAL_RCC_GPIOD_CLK_ENABLE();

  /*Configure GPIO pin Output Level */
  HAL_GPIO_WritePin(GPIOE, USER_LED_Pin|RUN_LED_Pin|TCRT5000_VCC_EN_Pin|XP_Pin
                          |XN_Pin|X_CCW_Pin|X_CW_Pin, GPIO_PIN_RESET);

  /*Configure GPIO pin Output Level */
  HAL_GPIO_WritePin(HXSCK_GPIO_Port, HXSCK_Pin, GPIO_PIN_RESET);

  /*Configure GPIO pin Output Level */
  HAL_GPIO_WritePin(GPIOB, L293DD_ENABLE1_Pin|Y_CW_Pin|Y_CCW_Pin|MS1_Pin, GPIO_PIN_RESET);

  /*Configure GPIO pin Output Level */
  HAL_GPIO_WritePin(GPIOD, MPU6050_AD0_Pin|MPU6050_AD1_Pin|MPU6050_AD2_Pin|YP_Pin
                          |YN_Pin|L293DD_ENABLE2_Pin|TMC_EN_Pin|DIR_Pin
                          |MS2_Pin|STEP_Pin, GPIO_PIN_RESET);

  /*Configure GPIO pins : USER_LED_Pin RUN_LED_Pin TCRT5000_VCC_EN_Pin XP_Pin
                           XN_Pin X_CCW_Pin X_CW_Pin */
  GPIO_InitStruct.Pin = USER_LED_Pin|RUN_LED_Pin|TCRT5000_VCC_EN_Pin|XP_Pin
                          |XN_Pin|X_CCW_Pin|X_CW_Pin;
  GPIO_InitStruct.Mode = GPIO_MODE_OUTPUT_PP;
  GPIO_InitStruct.Pull = GPIO_NOPULL;
  GPIO_InitStruct.Speed = GPIO_SPEED_FREQ_LOW;
  HAL_GPIO_Init(GPIOE, &GPIO_InitStruct);

  /*Configure GPIO pins : DHT_Pin ENDSTOP_INPUT_Pin */
  GPIO_InitStruct.Pin = DHT_Pin|ENDSTOP_INPUT_Pin;
  GPIO_InitStruct.Mode = GPIO_MODE_INPUT;
  GPIO_InitStruct.Pull = GPIO_NOPULL;
  HAL_GPIO_Init(GPIOC, &GPIO_InitStruct);

  /*Configure GPIO pin : HXSCK_Pin */
  GPIO_InitStruct.Pin = HXSCK_Pin;
  GPIO_InitStruct.Mode = GPIO_MODE_OUTPUT_PP;
  GPIO_InitStruct.Pull = GPIO_NOPULL;
  GPIO_InitStruct.Speed = GPIO_SPEED_FREQ_LOW;
  HAL_GPIO_Init(HXSCK_GPIO_Port, &GPIO_InitStruct);

  /*Configure GPIO pin : JS1_Pin */
  GPIO_InitStruct.Pin = JS1_Pin;
  GPIO_InitStruct.Mode = GPIO_MODE_IT_FALLING;
  GPIO_InitStruct.Pull = GPIO_PULLUP;
  HAL_GPIO_Init(JS1_GPIO_Port, &GPIO_InitStruct);

  /*Configure GPIO pins : HXDAT_Pin SDIO_CD_Pin */
  GPIO_InitStruct.Pin = HXDAT_Pin|SDIO_CD_Pin;
  GPIO_InitStruct.Mode = GPIO_MODE_INPUT;
  GPIO_InitStruct.Pull = GPIO_NOPULL;
  HAL_GPIO_Init(GPIOE, &GPIO_InitStruct);

  /*Configure GPIO pin : JS2_Pin */
  GPIO_InitStruct.Pin = JS2_Pin;
  GPIO_InitStruct.Mode = GPIO_MODE_IT_FALLING;
  GPIO_InitStruct.Pull = GPIO_PULLUP;
  HAL_GPIO_Init(JS2_GPIO_Port, &GPIO_InitStruct);

  /*Configure GPIO pins : L293DD_ENABLE1_Pin Y_CW_Pin Y_CCW_Pin MS1_Pin */
  GPIO_InitStruct.Pin = L293DD_ENABLE1_Pin|Y_CW_Pin|Y_CCW_Pin|MS1_Pin;
  GPIO_InitStruct.Mode = GPIO_MODE_OUTPUT_PP;
  GPIO_InitStruct.Pull = GPIO_NOPULL;
  GPIO_InitStruct.Speed = GPIO_SPEED_FREQ_LOW;
  HAL_GPIO_Init(GPIOB, &GPIO_InitStruct);

  /*Configure GPIO pins : MPU6050_AD0_Pin MPU6050_AD1_Pin MPU6050_AD2_Pin YP_Pin
                           YN_Pin L293DD_ENABLE2_Pin TMC_EN_Pin DIR_Pin
                           MS2_Pin STEP_Pin */
  GPIO_InitStruct.Pin = MPU6050_AD0_Pin|MPU6050_AD1_Pin|MPU6050_AD2_Pin|YP_Pin
                          |YN_Pin|L293DD_ENABLE2_Pin|TMC_EN_Pin|DIR_Pin
                          |MS2_Pin|STEP_Pin;
  GPIO_InitStruct.Mode = GPIO_MODE_OUTPUT_PP;
  GPIO_InitStruct.Pull = GPIO_NOPULL;
  GPIO_InitStruct.Speed = GPIO_SPEED_FREQ_LOW;
  HAL_GPIO_Init(GPIOD, &GPIO_InitStruct);

  /*Configure GPIO pins : ESY_N_Pin ESX_N_Pin */
  GPIO_InitStruct.Pin = ESY_N_Pin|ESX_N_Pin;
  GPIO_InitStruct.Mode = GPIO_MODE_IT_RISING_FALLING;
  GPIO_InitStruct.Pull = GPIO_NOPULL;
  HAL_GPIO_Init(GPIOD, &GPIO_InitStruct);

  /*Configure GPIO pins : P_M_ADC2_SIGN_Pin P_M_ADC1_SIGN_Pin */
  GPIO_InitStruct.Pin = P_M_ADC2_SIGN_Pin|P_M_ADC1_SIGN_Pin;
  GPIO_InitStruct.Mode = GPIO_MODE_INPUT;
  GPIO_InitStruct.Pull = GPIO_NOPULL;
  HAL_GPIO_Init(GPIOA, &GPIO_InitStruct);

  /*Configure GPIO pin : TMC_IND_Pin */
  GPIO_InitStruct.Pin = TMC_IND_Pin;
  GPIO_InitStruct.Mode = GPIO_MODE_IT_RISING;
  GPIO_InitStruct.Pull = GPIO_NOPULL;
  HAL_GPIO_Init(TMC_IND_GPIO_Port, &GPIO_InitStruct);

  /*Configure GPIO pin : TMC_DIAG_Pin */
  GPIO_InitStruct.Pin = TMC_DIAG_Pin;
  GPIO_InitStruct.Mode = GPIO_MODE_INPUT;
  GPIO_InitStruct.Pull = GPIO_NOPULL;
  HAL_GPIO_Init(TMC_DIAG_GPIO_Port, &GPIO_InitStruct);

  /*Configure GPIO pins : ESX_P_Pin ESY_P_Pin */
  GPIO_InitStruct.Pin = ESX_P_Pin|ESY_P_Pin;
  GPIO_InitStruct.Mode = GPIO_MODE_IT_RISING_FALLING;
  GPIO_InitStruct.Pull = GPIO_NOPULL;
  HAL_GPIO_Init(GPIOB, &GPIO_InitStruct);

  /* EXTI interrupt init*/
  HAL_NVIC_SetPriority(EXTI2_IRQn, 2, 0);
  HAL_NVIC_EnableIRQ(EXTI2_IRQn);

  HAL_NVIC_SetPriority(EXTI9_5_IRQn, 2, 0);
  HAL_NVIC_EnableIRQ(EXTI9_5_IRQn);

  HAL_NVIC_SetPriority(EXTI15_10_IRQn, 2, 0);
  HAL_NVIC_EnableIRQ(EXTI15_10_IRQn);

}

void Error_Handler(void)
{
  __disable_irq();
  while (1)
  {
  }
}

/************************ (C) COPYRIGHT STMicroelectronics *****END OF FILE****/
